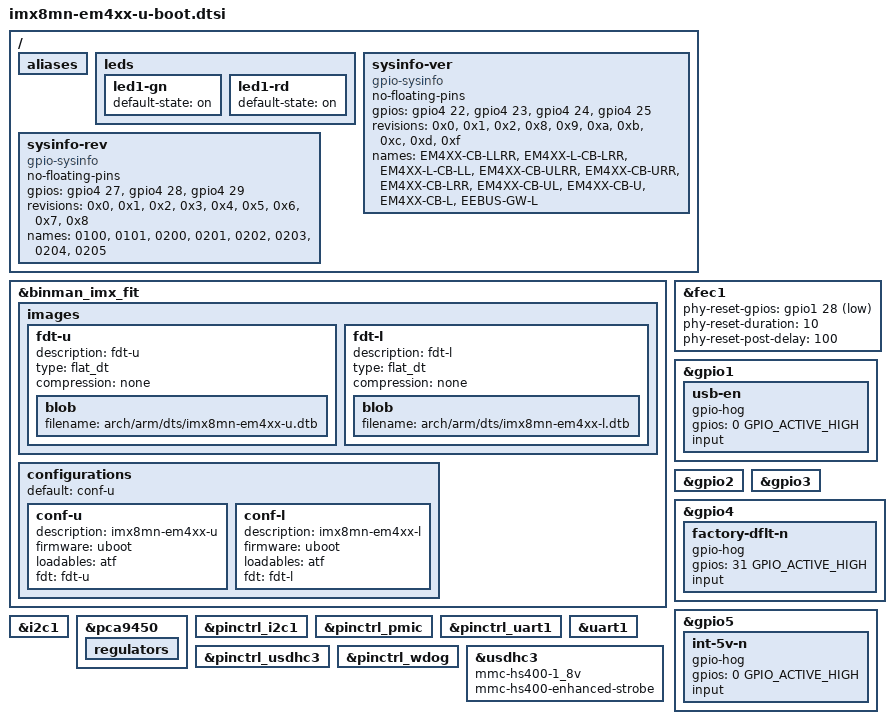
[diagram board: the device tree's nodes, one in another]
// SPDX-License-Identifier: GPL-2.0-or-later
/*
 * Copyright (c) 2023-2026 TQ-Systems GmbH <u-boot@ew.tq-group.com>,
 * D-82229 Seefeld, Germany.
 * Author: Michael Krummsdorf
 */

#include "imx8mn-u-boot.dtsi"

/ {
	aliases {
		/delete-property/ ethernet1;
	};

	leds {
		led1-gn {
			default-state = "on";
		};

		led1-rd {
			default-state = "on";
		};
	};

	/*
	 * sysinfo is not marked as bootph-all - we don't want
	 * early show_board_info() to use this info
	 */
	sysinfo-ver {
		compatible = "gpio-sysinfo";
		no-floating-pins;
		gpios =
			<&gpio4 22 GPIO_ACTIVE_HIGH>, /* HW.VER0 */
			<&gpio4 23 GPIO_ACTIVE_HIGH>, /* HW.VER1 */
			<&gpio4 24 GPIO_ACTIVE_HIGH>, /* HW.VER2 */
			<&gpio4 25 GPIO_ACTIVE_HIGH>; /* HW.VER3 */

		revisions = <0x0>, <0x1>, <0x2>, <0x8>, <0x9>, <0xa>, <0xb>, <0xc>, <0xd>, <0xf>;
		names = "EM4XX-CB-LLRR",
			"EM4XX-L-CB-LRR",
			"EM4XX-L-CB-LL",
			"EM4XX-CB-ULRR",
			"EM4XX-CB-URR",
			"EM4XX-CB-LRR",
			"EM4XX-CB-UL",
			"EM4XX-CB-U",
			"EM4XX-CB-L",
			"EEBUS-GW-L";
	};

	sysinfo-rev {
		compatible = "gpio-sysinfo";
		no-floating-pins;
		gpios =
			<&gpio4 27 GPIO_ACTIVE_HIGH>, /* HW.REV0 */
			<&gpio4 28 GPIO_ACTIVE_HIGH>, /* HW.REV1 */
			<&gpio4 29 GPIO_ACTIVE_HIGH>; /* HW.REV2 */

		revisions = <0x0>, <0x1>, <0x2>, <0x3>, <0x4>, <0x5>, <0x6>, <0x7>, <0x8>;
		names = "0100", "0101", "0200", "0201", "0202", "0203", "0204", "0205";
	};

};

&binman_imx_fit {
	images {
		fdt-u {
			description = "fdt-u";
			type = "flat_dt";
			compression = "none";
			blob {
				filename = "arch/arm/dts/imx8mn-em4xx-u.dtb";
			};
		};

		fdt-l {
			description = "fdt-l";
			type = "flat_dt";
			compression = "none";
			blob {
				filename = "arch/arm/dts/imx8mn-em4xx-l.dtb";
			};
		};
	};

	configurations {
		default = "conf-u";

		conf-u {
			description = "imx8mn-em4xx-u";
			firmware = "uboot";
			loadables = "atf";
			fdt = "fdt-u";
		};

		conf-l {
			description = "imx8mn-em4xx-l";
			firmware = "uboot";
			loadables = "atf";
			fdt = "fdt-l";
		};
	};
};

&fec1 {
	/* U-Boot network as fixed-link, use generic reset */
	phy-reset-gpios = <&gpio1 28 GPIO_ACTIVE_LOW>;
	phy-reset-duration = <10>;
	phy-reset-post-delay = <100>;
};

&gpio1 {
	bootph-pre-ram;

	usb-en {
		gpio-hog;
		gpios = <0 GPIO_ACTIVE_HIGH>;
		input;
	};
};

&gpio2 {
	bootph-pre-ram;
};

&gpio3 {
	bootph-pre-ram;
};

&gpio4 {
	bootph-pre-ram;
	/delete-node/ hw-ver-0-hog;
	/delete-node/ hw-ver-1-hog;
	/delete-node/ hw-ver-2-hog;
	/delete-node/ hw-ver-3-hog;
	/delete-node/ hw-rev-0-hog;
	/delete-node/ hw-rev-1-hog;
	/delete-node/ hw-rev-2-hog;

	factory-dflt-n {
		gpio-hog;
		gpios = <31 GPIO_ACTIVE_HIGH>;
		input;
	};
};

&gpio5 {
	bootph-pre-ram;

	int-5v-n {
		gpio-hog;
		gpios = <0 GPIO_ACTIVE_HIGH>;
		input;
	};
};

&i2c1 {
	bootph-pre-ram;
};

&pca9450 {
	bootph-pre-ram;

	regulators {
		bootph-pre-ram;
	};
};

&pinctrl_i2c1 {
	bootph-pre-ram;
};

&pinctrl_pmic {
	bootph-pre-ram;
};

&pinctrl_uart1 {
	bootph-pre-ram;
};

&pinctrl_usdhc3 {
	bootph-pre-ram;
};

&pinctrl_wdog {
	bootph-pre-ram;
};

&uart1 {
	bootph-pre-ram;
};

&usdhc3 {
	bootph-pre-ram;
	mmc-hs400-1_8v;
	mmc-hs400-enhanced-strobe;
};
